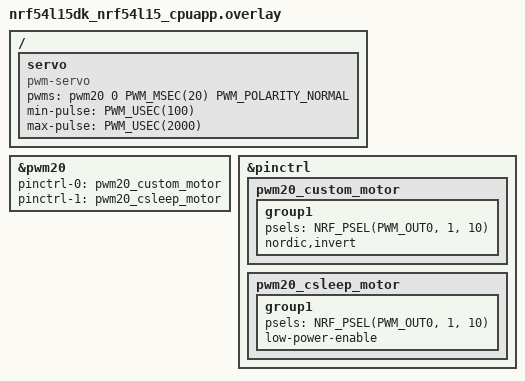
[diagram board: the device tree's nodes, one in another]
// To get started, press Ctrl+Space to bring up the completion menu and view the available nodes.

// You can also use the buttons in the sidebar to perform actions on nodes.
// Actions currently available include:

// * Enabling / disabling the node
// * Adding the bus to a bus
// * Removing the node
// * Connecting ADC channels

// For more help, browse the DeviceTree documentation at https://docs.zephyrproject.org/latest/guides/dts/index.html
// You can also visit the nRF DeviceTree extension documentation at https://docs.nordicsemi.com/bundle/nrf-connect-vscode/page/guides/ncs_configure_app.html#devicetree-support-in-the-extension

/ {
    servo: servo {
        compatible = "pwm-servo";
        pwms = <&pwm20 0 PWM_MSEC(20) PWM_POLARITY_NORMAL>;
        min-pulse = <PWM_USEC(100)>;
        max-pulse = <PWM_USEC(2000)>;
    };
};

/* STEP 5.3 - Configure which pins pwm20 should use */
&pwm20 {
    status = "okay";
    pinctrl-0 = <&pwm20_custom_motor>;
    pinctrl-1 = <&pwm20_csleep_motor>;
    pinctrl-names = "default", "sleep";
};

&pinctrl {
    pwm20_custom_motor: pwm20_custom_motor {
        group1 {
            psels = <NRF_PSEL(PWM_OUT0, 1, 10)>; /* Original is 1.10 */
            nordic,invert;
        };
    };

    pwm20_csleep_motor: pwm20_csleep_motor {
        group1 {
            psels = <NRF_PSEL(PWM_OUT0, 1, 10)>; 
            low-power-enable;
        };
    };
};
